AUTOSAR XML (schema 00051)
package /Components
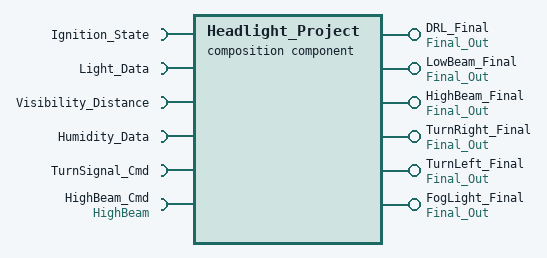
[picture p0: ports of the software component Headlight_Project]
  composition sw component type Headlight_Project
    6 x require port:
      Ignition_State: required-interface=Ignition_State
      Light_Data: required-interface=Light_Data
      Visibility_Distance: required-interface=Visibility_Distance
      Humidity_Data: required-interface=Humidity_Data
      TurnSignal_Cmd: required-interface=TurnSignal_Cmd
      HighBeam_Cmd: required-interface=HighBeam
    6 x provide port, all with provided-interface=Final_Out:
      DRL_Final
      LowBeam_Final
      HighBeam_Final
      TurnRight_Final
      TurnLeft_Final
      FogLight_Final
    component Sensor_Composition: type=Sensor_Composition
    component Ctrl: type=Ctrl
    component Actuator: type=Actuator
    connect Ctrl.DRL_Status_Out -> Actuator.DRL_Status_In
    connect Ctrl.LowBeam_Status_Out -> Actuator.LowBeam_Status_In
    connect Ctrl.HighBeam_Status_Out -> Actuator.HighBeam_Status_In
    connect Ctrl.TurnRight_Status_Out -> Actuator.TurnRight_Status_In
    connect Ctrl.TurnLeft_Status_Out -> Actuator.TurnLeft_Status_In
    connect Ctrl.FogLight_Status_Out -> Actuator.FogLight_Status_In
    connect Sensor_Composition.N_Detector_Out -> Ctrl.N_Detector_Out
    connect Sensor_Composition.AF_Detector_Out -> Ctrl.AF_Detector_Out
    delegate Actuator.DRL_Final <-> outer port DRL_Final
    delegate Actuator.LowBeam_Final <-> outer port LowBeam_Final
    delegate Actuator.HighBeam_Final <-> outer port HighBeam_Final
    delegate Actuator.TurnRight_Final <-> outer port TurnRight_Final
    delegate Actuator.TurnLeft_Final <-> outer port TurnLeft_Final
    delegate Actuator.FogLight_Final <-> outer port FogLight_Final
    delegate Sensor_Composition.Ignition_State <-> outer port Ignition_State
    delegate Ctrl.Ignition_State <-> outer port Ignition_State
    delegate Sensor_Composition.Light_Data <-> outer port Light_Data
    delegate Sensor_Composition.Visibility_Distance <-> outer port Visibility_Distance
    delegate Sensor_Composition.Humidity_Data <-> outer port Humidity_Data
    delegate Ctrl.HighBeam_Cmd <-> outer port HighBeam_Cmd
    delegate Ctrl.TurnSignal_Cmd <-> outer port TurnSignal_Cmd
